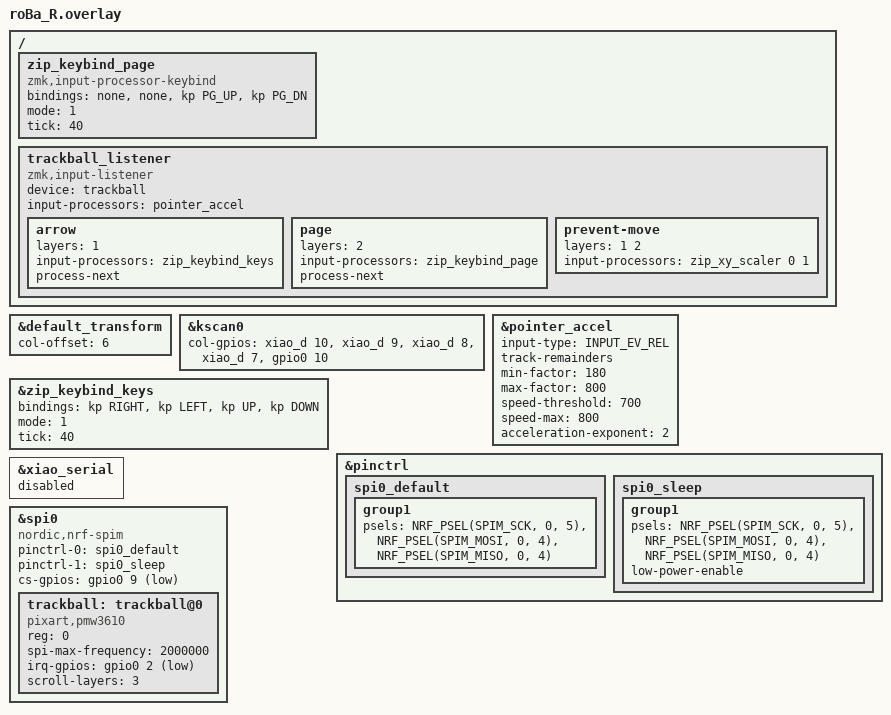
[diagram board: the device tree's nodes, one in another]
#include "roBa.dtsi"
#include <input/processors.dtsi>
#include <zephyr/dt-bindings/input/input-event-codes.h>
#include <behaviors/input_gestures_accel.dtsi>
#include <input/processors/zmk-input-processor-keybind.dtsi>

&default_transform {
    col-offset = <6>;
};

&kscan0 {
        col-gpios
            = <&xiao_d 10 GPIO_ACTIVE_HIGH>
            , <&xiao_d 9 GPIO_ACTIVE_HIGH>
            , <&xiao_d 8 GPIO_ACTIVE_HIGH>
            , <&xiao_d 7 GPIO_ACTIVE_HIGH>
            , <&gpio0 10 GPIO_ACTIVE_HIGH>
            ;
};

&pointer_accel {
    input-type = <INPUT_EV_REL>;
    track-remainders;
    min-factor = <180>;
    max-factor = <800>;
    speed-threshold = <700>;
    speed-max = <800>;
    acceleration-exponent = <2>;
};

/ {
  zip_keybind_page: zip_keybind_page {
    compatible = "zmk,input-processor-keybind";
    #input-processor-cells = <0>;
    bindings = <&none>, <&none>, <&kp PG_UP>, <&kp PG_DN>;
    mode = <1>;
    tick = <40>;
  };

    trackball_listener {
        status = "okay";
        compatible = "zmk,input-listener";
        device = <&trackball>;

        input-processors =
            <&pointer_accel>;

        arrow {
            layers = <1>;
            input-processors = <&zip_keybind_keys>;
            process-next;
        };

        page {
            layers = <2>;
            input-processors = <&zip_keybind_page>;
            process-next;
        };

        prevent-move {
            layers = <1 2>;
            input-processors = <&zip_xy_scaler 0 1>;
        };
    };
};

&zip_keybind_keys {
    bindings = <&kp RIGHT>, <&kp LEFT>, <&kp UP>, <&kp DOWN>;
    mode = <1>;
    tick = <40>;
};

&pinctrl {
    spi0_default: spi0_default {
        group1 {
            psels = <NRF_PSEL(SPIM_SCK, 0, 5)>,
                <NRF_PSEL(SPIM_MOSI, 0, 4)>,
                <NRF_PSEL(SPIM_MISO, 0, 4)>;
        };
    };

    spi0_sleep: spi0_sleep {
        group1 {
            psels = <NRF_PSEL(SPIM_SCK, 0, 5)>,
                <NRF_PSEL(SPIM_MOSI, 0, 4)>,
                <NRF_PSEL(SPIM_MISO, 0, 4)>;
            low-power-enable;
        };
    };
};

&xiao_serial { status = "disabled"; };

&spi0 {
    status = "okay";
    compatible = "nordic,nrf-spim";
    pinctrl-0 = <&spi0_default>;
    pinctrl-1 = <&spi0_sleep>;
    pinctrl-names = "default", "sleep";
    cs-gpios = <&gpio0 9 GPIO_ACTIVE_LOW>;

    trackball: trackball@0 {
        status = "okay";
        compatible = "pixart,pmw3610";
        reg = <0>;
        spi-max-frequency = <2000000>;
        irq-gpios = <&gpio0 2 (GPIO_ACTIVE_LOW | GPIO_PULL_UP)>;
        scroll-layers = <3>;
    };
};

